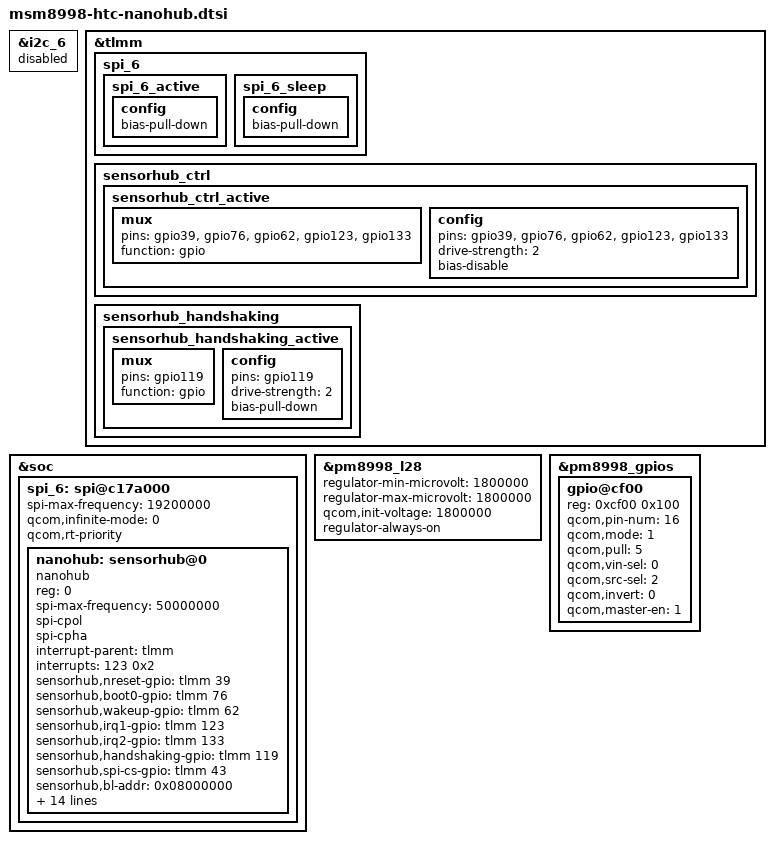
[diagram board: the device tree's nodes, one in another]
/* Copyright (c) 2016, The Linux Foundation. All rights reserved.
 *
 * This program is free software; you can redistribute it and/or modify
 * it under the terms of the GNU General Public License version 2 and
 * only version 2 as published by the Free Software Foundation.
 *
 * This program is distributed in the hope that it will be useful,
 * but WITHOUT ANY WARRANTY; without even the implied warranty of
 * MERCHANTABILITY or FITNESS FOR A PARTICULAR PURPOSE.  See the
 * GNU General Public License for more details.
 */

/*
 * msm8998-htc-nanohub : nanohub config
 */

&i2c_6 {
	status = "disabled";
};

&tlmm {
	spi_6 {
		spi_6_active: spi_6_active {
			config {
				bias-pull-down;
			};
		};

		spi_6_sleep: spi_6_sleep {
			config {
				bias-pull-down;
			};
		};
	};

	sensorhub_ctrl {
	/* NRST, BOOT0, AP2SH, SH2AP, SH2APNW */
		sensorhub_ctrl_active: sensorhub_ctrl_active {
			mux {
				pins = "gpio39", "gpio76", "gpio62", "gpio123", "gpio133";
				function = "gpio";
			};

			config {
				pins = "gpio39", "gpio76", "gpio62", "gpio123", "gpio133";
				drive-strength = <2>;
				bias-disable;
			};
		};
	};

	sensorhub_handshaking {
	/* HANDSHAKING */
		sensorhub_handshaking_active: sensorhub_handshaking_active {
			mux {
				pins = "gpio119";
				function = "gpio";
			};

			config {
				pins = "gpio119";
				drive-strength = <2>;
				bias-pull-down;
			};
		};
	};
};

&soc {
	spi_6: spi@c17a000 { /* BLSP1 QUP6 */
		status = "okay";
		spi-max-frequency = <19200000>;
		qcom,infinite-mode = <0>;
		qcom,rt-priority;
	};
};

&spi_6 {
	nanohub: sensorhub@0 {
		compatible = "nanohub";
		reg = <0>;
		spi-max-frequency = <50000000>;
		spi-cpol;
		spi-cpha;

		interrupt-parent = <&tlmm>;
		interrupts = <123 0x2>;
		sensorhub,nreset-gpio = <&tlmm 39 0x00>;
		sensorhub,boot0-gpio = <&tlmm 76 0x00>;
		sensorhub,wakeup-gpio = <&tlmm 62 0x00>;
		sensorhub,irq1-gpio = <&tlmm 123 0x00>;
		sensorhub,irq2-gpio = <&tlmm 133 0x00>;
		sensorhub,handshaking-gpio = <&tlmm 119 0x00>;
		sensorhub,spi-cs-gpio = <&tlmm 43 0x00>;
		sensorhub,bl-addr = <0x08000000>;
		sensorhub,kernel-addr = <0x0800C000>;
		sensorhub,shared-addr = <0x08040000>;
		sensorhub,flash-banks = <0 0x08000000 0x04000>,
			<3 0x0800C000 0x04000>,
			<4 0x08010000 0x10000>,
			<5 0x08020000 0x20000>;
		sensorhub,num-flash-banks = <4>;
		sensorhub,shared-flash-banks = <6 0x08040000 0x20000>,
			<7 0x08060000 0x20000>,
			<8 0x08080000 0x20000>,
			<9 0x080A0000 0x20000>,
			<10 0x080C0000 0x20000>,
			<11 0x080E0000 0x20000>;
		sensorhub,num-shared-flash-banks = <6>;
		sensorhub,gesture-vibrate-ms = <25>;

		pinctrl-names = "default";
		pinctrl-0 = <&sensorhub_ctrl_active &sensorhub_handshaking_active>;
	};
};

&pm8998_l28 {
	regulator-min-microvolt = <1800000>;
	regulator-max-microvolt = <1800000>;
	qcom,init-voltage = <1800000>;
	regulator-always-on;
	status = "okay";
};

/*
&pm8998_l19 {
	regulator-min-microvolt = <2850000>;
	regulator-max-microvolt = <2850000>;
	qcom,init-voltage = <2850000>;
	regulator-always-on;
	status = "okay";
};
*/

&pm8998_gpios {
	gpio@cf00 {
		reg = <0xcf00 0x100>;
		qcom,pin-num = <16>;
		qcom,mode = <1>; /* Output */
		qcom,pull = <5>; /* No Pull */
		qcom,vin-sel = <0>; /* VIN1 GPIO_LV */
		qcom,src-sel = <2>; /* Special Funtion 1 */
		qcom,invert = <0>; /* Invert */
		qcom,master-en = <1>; /* Enable GPIO */
		status = "okay";
	};
};
